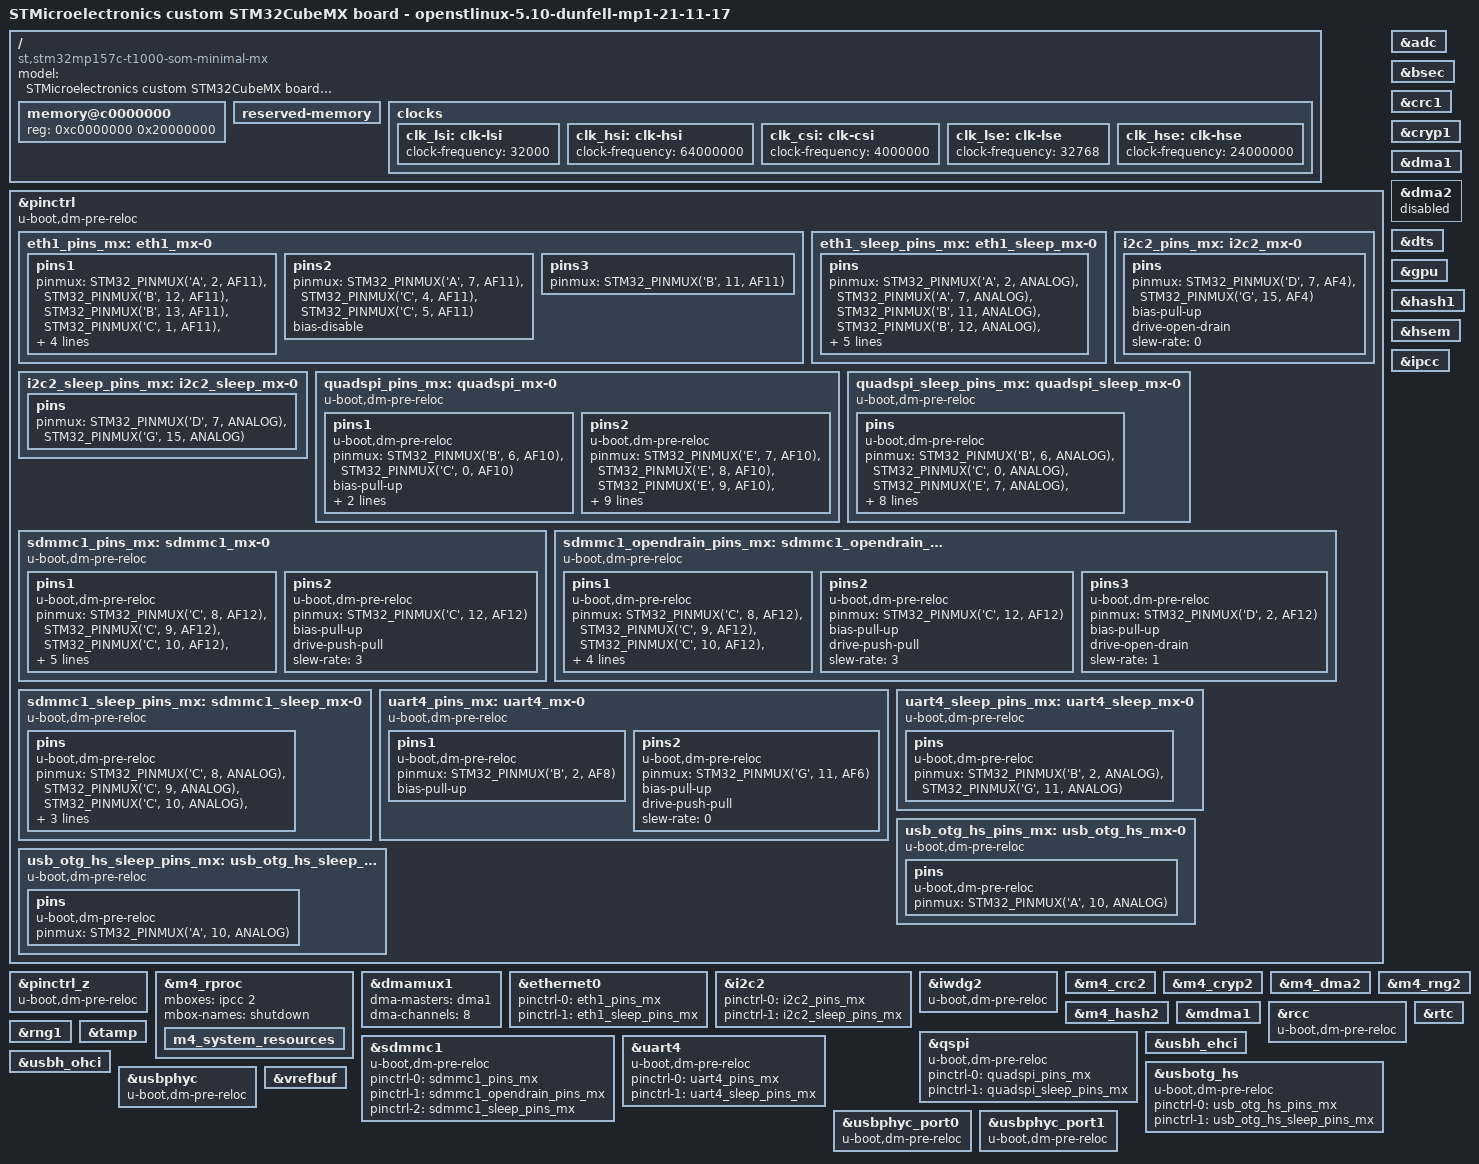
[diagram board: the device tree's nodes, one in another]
/* SPDX-License-Identifier: (GPL-2.0+ OR BSD-3-Clause) */
/*
 * Copyright (C) STMicroelectronics 2022 - All Rights Reserved
 * Author: STM32CubeMX code generation for STMicroelectronics.
 */

/* For more information on Device Tree configuration, please refer to
 * https://wiki.st.com/stm32mpu/wiki/Category:Device_tree_configuration
 */

/dts-v1/;
#include <dt-bindings/pinctrl/stm32-pinfunc.h>

#include "stm32mp157.dtsi"
#include "stm32mp15xc.dtsi"
#include "stm32mp15xxad-pinctrl.dtsi"
#include "stm32mp15-m4-srm.dtsi"

/* USER CODE BEGIN includes */
/* USER CODE END includes */

/ {
	model = "STMicroelectronics custom STM32CubeMX board - openstlinux-5.10-dunfell-mp1-21-11-17";
	compatible = "st,stm32mp157c-t1000-som-minimal-mx", "st,stm32mp157";

	memory@c0000000 {
		device_type = "memory";
		reg = <0xc0000000 0x20000000>;

		/* USER CODE BEGIN memory */
		/* USER CODE END memory */
	};

	reserved-memory {
		#address-cells = <1>;
		#size-cells = <1>;
		ranges;

		/* USER CODE BEGIN reserved-memory */
		/* USER CODE END reserved-memory */
	};

	/* USER CODE BEGIN root */
	/* USER CODE END root */

	clocks {
		/* USER CODE BEGIN clocks */
		/* USER CODE END clocks */

#ifndef CONFIG_TFABOOT
		clk_lsi: clk-lsi {
			clock-frequency = <32000>;
		};
		clk_hsi: clk-hsi {
			clock-frequency = <64000000>;
		};
		clk_csi: clk-csi {
			clock-frequency = <4000000>;
		};
		clk_lse: clk-lse {
			clock-frequency = <32768>;
		};
		clk_hse: clk-hse {
			clock-frequency = <24000000>;
		};
#endif	/*CONFIG_TFABOOT*/
	};

}; /*root*/

&pinctrl {
	u-boot,dm-pre-reloc;

	eth1_pins_mx: eth1_mx-0 {
		pins1 {
			pinmux = <STM32_PINMUX('A', 2, AF11)>, /* ETH1_MDIO */
					 <STM32_PINMUX('B', 12, AF11)>, /* ETH1_TXD0 */
					 <STM32_PINMUX('B', 13, AF11)>, /* ETH1_TXD1 */
					 <STM32_PINMUX('C', 1, AF11)>, /* ETH1_MDC */
					 <STM32_PINMUX('G', 8, AF2)>; /* ETH1_CLK */
			bias-disable;
			drive-push-pull;
			slew-rate = <1>;
		};
		pins2 {
			pinmux = <STM32_PINMUX('A', 7, AF11)>, /* ETH1_CRS_DV */
					 <STM32_PINMUX('C', 4, AF11)>, /* ETH1_RXD0 */
					 <STM32_PINMUX('C', 5, AF11)>; /* ETH1_RXD1 */
			bias-disable;
		};
		pins3 {
			pinmux = <STM32_PINMUX('B', 11, AF11)>; /* ETH1_TX_EN */
		};
	};

	eth1_sleep_pins_mx: eth1_sleep_mx-0 {
		pins {
			pinmux = <STM32_PINMUX('A', 2, ANALOG)>, /* ETH1_MDIO */
					 <STM32_PINMUX('A', 7, ANALOG)>, /* ETH1_CRS_DV */
					 <STM32_PINMUX('B', 11, ANALOG)>, /* ETH1_TX_EN */
					 <STM32_PINMUX('B', 12, ANALOG)>, /* ETH1_TXD0 */
					 <STM32_PINMUX('B', 13, ANALOG)>, /* ETH1_TXD1 */
					 <STM32_PINMUX('C', 1, ANALOG)>, /* ETH1_MDC */
					 <STM32_PINMUX('C', 4, ANALOG)>, /* ETH1_RXD0 */
					 <STM32_PINMUX('C', 5, ANALOG)>, /* ETH1_RXD1 */
					 <STM32_PINMUX('G', 8, ANALOG)>; /* ETH1_CLK */
		};
	};

	i2c2_pins_mx: i2c2_mx-0 {
		pins {
			pinmux = <STM32_PINMUX('D', 7, AF4)>, /* I2C2_SCL */
					 <STM32_PINMUX('G', 15, AF4)>; /* I2C2_SDA */
			bias-pull-up;
			drive-open-drain;
			slew-rate = <0>;
		};
	};

	i2c2_sleep_pins_mx: i2c2_sleep_mx-0 {
		pins {
			pinmux = <STM32_PINMUX('D', 7, ANALOG)>, /* I2C2_SCL */
					 <STM32_PINMUX('G', 15, ANALOG)>; /* I2C2_SDA */
		};
	};

	quadspi_pins_mx: quadspi_mx-0 {
		u-boot,dm-pre-reloc;
		pins1 {
			u-boot,dm-pre-reloc;
			pinmux = <STM32_PINMUX('B', 6, AF10)>, /* QUADSPI_BK1_NCS */
					 <STM32_PINMUX('C', 0, AF10)>; /* QUADSPI_BK2_NCS */
			bias-pull-up;
			drive-push-pull;
			slew-rate = <3>;
		};
		pins2 {
			u-boot,dm-pre-reloc;
			pinmux = <STM32_PINMUX('E', 7, AF10)>, /* QUADSPI_BK2_IO0 */
					 <STM32_PINMUX('E', 8, AF10)>, /* QUADSPI_BK2_IO1 */
					 <STM32_PINMUX('E', 9, AF10)>, /* QUADSPI_BK2_IO2 */
					 <STM32_PINMUX('E', 10, AF10)>, /* QUADSPI_BK2_IO3 */
					 <STM32_PINMUX('F', 6, AF9)>, /* QUADSPI_BK1_IO3 */
					 <STM32_PINMUX('F', 7, AF9)>, /* QUADSPI_BK1_IO2 */
					 <STM32_PINMUX('F', 8, AF10)>, /* QUADSPI_BK1_IO0 */
					 <STM32_PINMUX('F', 9, AF10)>, /* QUADSPI_BK1_IO1 */
					 <STM32_PINMUX('F', 10, AF9)>; /* QUADSPI_CLK */
			bias-disable;
			drive-push-pull;
			slew-rate = <3>;
		};
	};

	quadspi_sleep_pins_mx: quadspi_sleep_mx-0 {
		u-boot,dm-pre-reloc;
		pins {
			u-boot,dm-pre-reloc;
			pinmux = <STM32_PINMUX('B', 6, ANALOG)>, /* QUADSPI_BK1_NCS */
					 <STM32_PINMUX('C', 0, ANALOG)>, /* QUADSPI_BK2_NCS */
					 <STM32_PINMUX('E', 7, ANALOG)>, /* QUADSPI_BK2_IO0 */
					 <STM32_PINMUX('E', 8, ANALOG)>, /* QUADSPI_BK2_IO1 */
					 <STM32_PINMUX('E', 9, ANALOG)>, /* QUADSPI_BK2_IO2 */
					 <STM32_PINMUX('E', 10, ANALOG)>, /* QUADSPI_BK2_IO3 */
					 <STM32_PINMUX('F', 6, ANALOG)>, /* QUADSPI_BK1_IO3 */
					 <STM32_PINMUX('F', 7, ANALOG)>, /* QUADSPI_BK1_IO2 */
					 <STM32_PINMUX('F', 8, ANALOG)>, /* QUADSPI_BK1_IO0 */
					 <STM32_PINMUX('F', 9, ANALOG)>, /* QUADSPI_BK1_IO1 */
					 <STM32_PINMUX('F', 10, ANALOG)>; /* QUADSPI_CLK */
		};
	};

	sdmmc1_pins_mx: sdmmc1_mx-0 {
		u-boot,dm-pre-reloc;
		pins1 {
			u-boot,dm-pre-reloc;
			pinmux = <STM32_PINMUX('C', 8, AF12)>, /* SDMMC1_D0 */
					 <STM32_PINMUX('C', 9, AF12)>, /* SDMMC1_D1 */
					 <STM32_PINMUX('C', 10, AF12)>, /* SDMMC1_D2 */
					 <STM32_PINMUX('C', 11, AF12)>, /* SDMMC1_D3 */
					 <STM32_PINMUX('D', 2, AF12)>; /* SDMMC1_CMD */
			bias-pull-up;
			drive-push-pull;
			slew-rate = <1>;
		};
		pins2 {
			u-boot,dm-pre-reloc;
			pinmux = <STM32_PINMUX('C', 12, AF12)>; /* SDMMC1_CK */
			bias-pull-up;
			drive-push-pull;
			slew-rate = <3>;
		};
	};

	sdmmc1_opendrain_pins_mx: sdmmc1_opendrain_mx-0 {
		u-boot,dm-pre-reloc;
		pins1 {
			u-boot,dm-pre-reloc;
			pinmux = <STM32_PINMUX('C', 8, AF12)>, /* SDMMC1_D0 */
					 <STM32_PINMUX('C', 9, AF12)>, /* SDMMC1_D1 */
					 <STM32_PINMUX('C', 10, AF12)>, /* SDMMC1_D2 */
					 <STM32_PINMUX('C', 11, AF12)>; /* SDMMC1_D3 */
			bias-pull-up;
			drive-push-pull;
			slew-rate = <1>;
		};
		pins2 {
			u-boot,dm-pre-reloc;
			pinmux = <STM32_PINMUX('C', 12, AF12)>; /* SDMMC1_CK */
			bias-pull-up;
			drive-push-pull;
			slew-rate = <3>;
		};
		pins3 {
			u-boot,dm-pre-reloc;
			pinmux = <STM32_PINMUX('D', 2, AF12)>; /* SDMMC1_CMD */
			bias-pull-up;
			drive-open-drain;
			slew-rate = <1>;
		};
	};

	sdmmc1_sleep_pins_mx: sdmmc1_sleep_mx-0 {
		u-boot,dm-pre-reloc;
		pins {
			u-boot,dm-pre-reloc;
			pinmux = <STM32_PINMUX('C', 8, ANALOG)>, /* SDMMC1_D0 */
					 <STM32_PINMUX('C', 9, ANALOG)>, /* SDMMC1_D1 */
					 <STM32_PINMUX('C', 10, ANALOG)>, /* SDMMC1_D2 */
					 <STM32_PINMUX('C', 11, ANALOG)>, /* SDMMC1_D3 */
					 <STM32_PINMUX('C', 12, ANALOG)>, /* SDMMC1_CK */
					 <STM32_PINMUX('D', 2, ANALOG)>; /* SDMMC1_CMD */
		};
	};

	uart4_pins_mx: uart4_mx-0 {
		u-boot,dm-pre-reloc;
		pins1 {
			u-boot,dm-pre-reloc;
			pinmux = <STM32_PINMUX('B', 2, AF8)>; /* UART4_RX */
			bias-pull-up;
		};
		pins2 {
			u-boot,dm-pre-reloc;
			pinmux = <STM32_PINMUX('G', 11, AF6)>; /* UART4_TX */
			bias-pull-up;
			drive-push-pull;
			slew-rate = <0>;
		};
	};

	uart4_sleep_pins_mx: uart4_sleep_mx-0 {
		u-boot,dm-pre-reloc;
		pins {
			u-boot,dm-pre-reloc;
			pinmux = <STM32_PINMUX('B', 2, ANALOG)>, /* UART4_RX */
					 <STM32_PINMUX('G', 11, ANALOG)>; /* UART4_TX */
		};
	};

	usb_otg_hs_pins_mx: usb_otg_hs_mx-0 {
		u-boot,dm-pre-reloc;
		pins {
			u-boot,dm-pre-reloc;
			pinmux = <STM32_PINMUX('A', 10, ANALOG)>; /* USB_OTG_HS_ID */
		};
	};

	usb_otg_hs_sleep_pins_mx: usb_otg_hs_sleep_mx-0 {
		u-boot,dm-pre-reloc;
		pins {
			u-boot,dm-pre-reloc;
			pinmux = <STM32_PINMUX('A', 10, ANALOG)>; /* USB_OTG_HS_ID */
		};
	};

	/* USER CODE BEGIN pinctrl */
	/* USER CODE END pinctrl */
};

&pinctrl_z {
	u-boot,dm-pre-reloc;

	/* USER CODE BEGIN pinctrl_z */
	/* USER CODE END pinctrl_z */
};

&m4_rproc{
	/*Restriction: "memory-region" property is not managed - please to use User-Section if needed*/
	mboxes = <&ipcc 2>;
	mbox-names = "shutdown";
	status = "okay";

	/* USER CODE BEGIN m4_rproc */
	/* USER CODE END m4_rproc */

	m4_system_resources{
		status = "okay";

		/* USER CODE BEGIN m4_system_resources */
		/* USER CODE END m4_system_resources */
	};
};

&adc{
	status = "okay";

	/* USER CODE BEGIN adc */
	/* USER CODE END adc */
};

&bsec{
	status = "okay";

	/* USER CODE BEGIN bsec */
	/* USER CODE END bsec */
};

&crc1{
	status = "okay";

	/* USER CODE BEGIN crc1 */
	/* USER CODE END crc1 */
};

&cryp1{
	status = "okay";

	/* USER CODE BEGIN cryp1 */
	/* USER CODE END cryp1 */
};

&dma1{
	status = "okay";

	/* USER CODE BEGIN dma1 */
	/* USER CODE END dma1 */
};

&dma2{
	status = "disabled";

	/* USER CODE BEGIN dma2 */
	/* USER CODE END dma2 */
};

&dmamux1{
	status = "okay";

	dma-masters = <&dma1>;
	dma-channels = <8>;

	/* USER CODE BEGIN dmamux1 */
	/* USER CODE END dmamux1 */
};

&dts{
	status = "okay";

	/* USER CODE BEGIN dts */
	/* USER CODE END dts */
};

&ethernet0{
	pinctrl-names = "default", "sleep";
	pinctrl-0 = <&eth1_pins_mx>;
	pinctrl-1 = <&eth1_sleep_pins_mx>;
	status = "okay";

	/* USER CODE BEGIN ethernet0 */
	/* USER CODE END ethernet0 */
};

&gpu{
	status = "okay";

	/* USER CODE BEGIN gpu */
	/* USER CODE END gpu */
};

&hash1{
	status = "okay";

	/* USER CODE BEGIN hash1 */
	/* USER CODE END hash1 */
};

&hsem{
	status = "okay";

	/* USER CODE BEGIN hsem */
	/* USER CODE END hsem */
};

&i2c2{
	pinctrl-names = "default", "sleep";
	pinctrl-0 = <&i2c2_pins_mx>;
	pinctrl-1 = <&i2c2_sleep_pins_mx>;
	status = "okay";

	/* USER CODE BEGIN i2c2 */
	/* USER CODE END i2c2 */
};

&ipcc{
	status = "okay";

	/* USER CODE BEGIN ipcc */
	/* USER CODE END ipcc */
};

&iwdg2{
	u-boot,dm-pre-reloc;
	status = "okay";

	/* USER CODE BEGIN iwdg2 */
	/* USER CODE END iwdg2 */
};

&m4_crc2{
	status = "okay";

	/* USER CODE BEGIN m4_crc2 */
	/* USER CODE END m4_crc2 */
};

&m4_cryp2{
	status = "okay";

	/* USER CODE BEGIN m4_cryp2 */
	/* USER CODE END m4_cryp2 */
};

&m4_dma2{
	status = "okay";

	/* USER CODE BEGIN m4_dma2 */
	/* USER CODE END m4_dma2 */
};

&m4_hash2{
	status = "okay";

	/* USER CODE BEGIN m4_hash2 */
	/* USER CODE END m4_hash2 */
};

&m4_rng2{
	status = "okay";

	/* USER CODE BEGIN m4_rng2 */
	/* USER CODE END m4_rng2 */
};

&mdma1{
	status = "okay";

	/* USER CODE BEGIN mdma1 */
	/* USER CODE END mdma1 */
};

&qspi{
	u-boot,dm-pre-reloc;
	pinctrl-names = "default", "sleep";
	pinctrl-0 = <&quadspi_pins_mx>;
	pinctrl-1 = <&quadspi_sleep_pins_mx>;
	status = "okay";

	/* USER CODE BEGIN qspi */
	/* USER CODE END qspi */
};

&rcc{
	u-boot,dm-pre-reloc;
	status = "okay";

	/* USER CODE BEGIN rcc */
	/* USER CODE END rcc */
};

&rng1{
	status = "okay";

	/* USER CODE BEGIN rng1 */
	/* USER CODE END rng1 */
};

&rtc{
	status = "okay";

	/* USER CODE BEGIN rtc */
	/* USER CODE END rtc */
};

&sdmmc1{
	u-boot,dm-pre-reloc;
	pinctrl-names = "default", "opendrain", "sleep";
	pinctrl-0 = <&sdmmc1_pins_mx>;
	pinctrl-1 = <&sdmmc1_opendrain_pins_mx>;
	pinctrl-2 = <&sdmmc1_sleep_pins_mx>;
	status = "okay";

	/* USER CODE BEGIN sdmmc1 */
	/* USER CODE END sdmmc1 */
};

&tamp{
	status = "okay";

	/* USER CODE BEGIN tamp */
	/* USER CODE END tamp */
};

&uart4{
	u-boot,dm-pre-reloc;
	pinctrl-names = "default", "sleep";
	pinctrl-0 = <&uart4_pins_mx>;
	pinctrl-1 = <&uart4_sleep_pins_mx>;
	status = "okay";

	/* USER CODE BEGIN uart4 */
	/* USER CODE END uart4 */
};

&usbh_ehci{
	status = "okay";

	/* USER CODE BEGIN usbh_ehci */
	/* USER CODE END usbh_ehci */
};

&usbh_ohci{
	status = "okay";

	/* USER CODE BEGIN usbh_ohci */
	/* USER CODE END usbh_ohci */
};

&usbotg_hs{
	u-boot,dm-pre-reloc;
	pinctrl-names = "default", "sleep";
	pinctrl-0 = <&usb_otg_hs_pins_mx>;
	pinctrl-1 = <&usb_otg_hs_sleep_pins_mx>;
	status = "okay";

	/* USER CODE BEGIN usbotg_hs */
	/* USER CODE END usbotg_hs */
};

&usbphyc{
	u-boot,dm-pre-reloc;
	status = "okay";

	/* USER CODE BEGIN usbphyc */
	/* USER CODE END usbphyc */
};

&usbphyc_port0{
	u-boot,dm-pre-reloc;
	status = "okay";

	/* USER CODE BEGIN usbphyc_port0 */
	/* USER CODE END usbphyc_port0 */
};

&usbphyc_port1{
	u-boot,dm-pre-reloc;
	status = "okay";

	/* USER CODE BEGIN usbphyc_port1 */
	/* USER CODE END usbphyc_port1 */
};

&vrefbuf{
	status = "okay";

	/* USER CODE BEGIN vrefbuf */
	/* USER CODE END vrefbuf */
};

/* USER CODE BEGIN addons */
/* USER CODE END addons */

